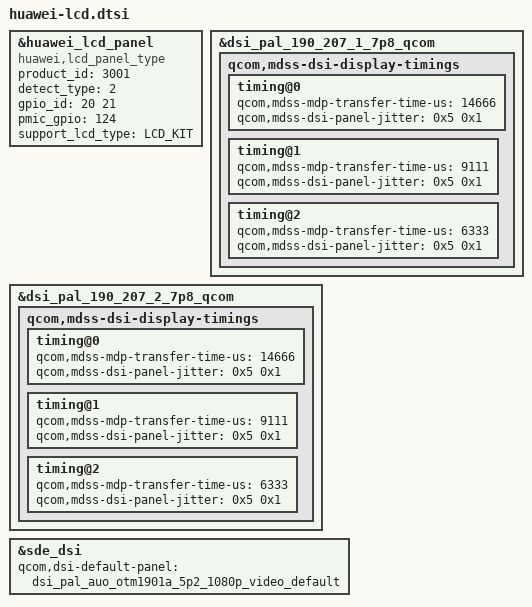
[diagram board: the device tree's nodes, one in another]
#include "../../../lcdkit3.0/pal/devkit_lcd_kit.dtsi"
&huawei_lcd_panel {
	compatible = "huawei,lcd_panel_type";
	/* auto_key_info @ name: product_id type: uint32 default: 0 */
	product_id = <3001>;
	detect_type = <2>;
	/* auto_key_info @ name: gpio_id[2] type: int default: 0 */
	gpio_id = <20 21>;
	/* auto_key_info @ name: pmic_gpio type: uint32 default: 0 */
	pmic_gpio = <124>;
	support_lcd_type = "LCD_KIT";
};

&dsi_pal_190_207_1_7p8_qcom {
        qcom,mdss-dsi-display-timings {
                timing@0 {
                        qcom,mdss-mdp-transfer-time-us = <14666>;
                        qcom,mdss-dsi-panel-jitter = <0x5 0x1>;
                };

                timing@1 {
                        qcom,mdss-mdp-transfer-time-us = <9111>;
                        qcom,mdss-dsi-panel-jitter = <0x5 0x1>;
                };

                timing@2 {
                        qcom,mdss-mdp-transfer-time-us = <6333>;
                        qcom,mdss-dsi-panel-jitter = <0x5 0x1>;
                };
        };
};

&dsi_pal_190_207_2_7p8_qcom {
        qcom,mdss-dsi-display-timings {
                timing@0 {
                        qcom,mdss-mdp-transfer-time-us = <14666>;
                        qcom,mdss-dsi-panel-jitter = <0x5 0x1>;
                };

                timing@1 {
                        qcom,mdss-mdp-transfer-time-us = <9111>;
                        qcom,mdss-dsi-panel-jitter = <0x5 0x1>;
                };

                timing@2 {
                        qcom,mdss-mdp-transfer-time-us = <6333>;
                        qcom,mdss-dsi-panel-jitter = <0x5 0x1>;
                };
        };
};

&sde_dsi {
	qcom,dsi-default-panel = <&dsi_pal_auo_otm1901a_5p2_1080p_video_default>;
};
